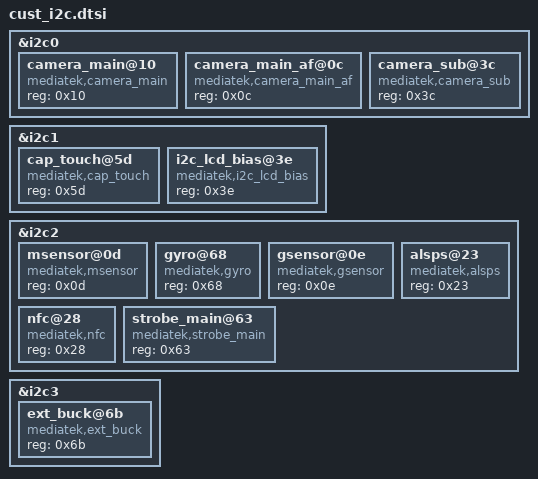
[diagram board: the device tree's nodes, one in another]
/*
 * Generated by MTK SP Drv_CodeGen Version 03.13.6	for MT6735M. Copyright MediaTek Inc. (C) 2013.
 * Fri Feb 22 18:03:05 2019
 * Do Not Modify the File.
 */

/*************************
 * I2C DTSI File
*************************/

&i2c0 {
	#address-cells = <1>;
	#size-cells = <0>;
	camera_main@10 {
		compatible = "mediatek,camera_main";
		reg = <0x10>;
		status = "okay";
	};
	camera_main_af@0c {
		compatible = "mediatek,camera_main_af";
		reg = <0x0c>;
		status = "okay";
	};
	camera_sub@3c {
		compatible = "mediatek,camera_sub";
		reg = <0x3c>;
		status = "okay";
	};
};

&i2c1 {
	#address-cells = <1>;
	#size-cells = <0>;
	cap_touch@5d {
		compatible = "mediatek,cap_touch";
		reg = <0x5d>;
		status = "okay";
	};
	i2c_lcd_bias@3e {
		compatible = "mediatek,i2c_lcd_bias";
		reg = <0x3e>;
		status = "okay";
	};
};

&i2c2 {
	#address-cells = <1>;
	#size-cells = <0>;
	msensor@0d {
		compatible = "mediatek,msensor";
		reg = <0x0d>;
		status = "okay";
	};
	gyro@68 {
		compatible = "mediatek,gyro";
		reg = <0x68>;
		status = "okay";
	};
	gsensor@0e {
		compatible = "mediatek,gsensor";
		reg = <0x0e>;
		status = "okay";
	};
	alsps@23 {
		compatible = "mediatek,alsps";
		reg = <0x23>;
		status = "okay";
	};
	nfc@28 {
		compatible = "mediatek,nfc";
		reg = <0x28>;
		status = "okay";
	};
	strobe_main@63 {
		compatible = "mediatek,strobe_main";
		reg = <0x63>;
		status = "okay";
	};
};

&i2c3 {
	#address-cells = <1>;
	#size-cells = <0>;
	ext_buck@6b {
		compatible = "mediatek,ext_buck";
		reg = <0x6b>;
		status = "okay";
	};
};

